# STM32WBA25 register map
File version: 1.0
CPU: CM33 r0p1, little endian, MPU, FPU, 4 interrupt priority bits
Registers are 32-bit, read-write, reset 0x0 unless marked. A register's access mark holds for its fields unless they carry their own. Offsets are from the block's base; [hi:lo] are bit positions; {n}, {i} and the like mark numbered series.

## SYSCFG — SYSCFG address block description
Base 0x46000400
Same registers: SEC_SYSCFG 0x56000400
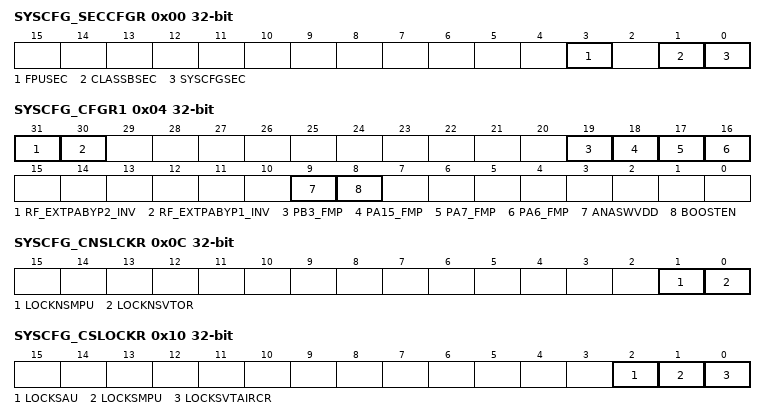
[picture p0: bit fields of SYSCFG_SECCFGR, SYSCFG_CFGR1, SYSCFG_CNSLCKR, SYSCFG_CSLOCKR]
0x00 SYSCFG_SECCFGR — SYSCFG secure configuration register
  [3] FPUSEC — FPU security
    0=SYSCFG_FPUIMR register can be read and written by secure and nonsecure access; 1=SYSCFG_FPUIMR register can be read and written by secure access only
  [1] CLASSBSEC — Class B security
    0=SYSCFG_CFGR2 register can be read and written by secure and nonsecure access; 1=SYSCFG_CFGR2 register can be read and written by secure access only
  [0] SYSCFGSEC — SYSCFG clock control, memory erase status and compensation cell registers security
    0=SYSCFG configuration clock in RCC registers, SYSCFG_MESR and SYSCFG_CCCSR, SYSCFG_CCVR and SYSCFG_CCCR can be read and written by secure and nonsecure access; 1=SYSCFG configuration clock in RCC registers, SYSCFG_MESR and SYSCFG_CCCSR, SYSCFG_CCVR and SYSCFG_CCCR can be read and written by secure access only
0x04 SYSCFG_CFGR1 — SYSCFG configuration register 1
  [31] RF_EXTPABYP2_INV — signal RF_EXTPABYP2 inversion selection.
    0=RF_EXTPABYP2 not inverted; 1=RF_EXTPABYP2 inverted
  [30] RF_EXTPABYP1_INV — signal RF_EXTPABYP1 inversion selection.
    0=RF_EXTPABYP1 not inverted; 1=RF_EXTPABYP1 inverted
  [19] PB3_FMP — Fast-mode Plus drive capability activation on PB3
    0=PB3 pin operates in standard mode when not used by I2C peripheral; 1=Fast-mode Plus mode is enabled on PAB3 pin and the GPIO speed control is bypassed
  [18] PA15_FMP — Fast-mode Plus drive capability activation on PA15
    0=PA15 pin operates in standard mode when not used by I2C peripheral; 1=Fast-mode Plus mode is enabled on PA15 pin and the GPIO speed control is bypassed
  [17] PA7_FMP — Fast-mode Plus drive capability activation on PA7
    0=PA7 pin operates in standard mode when not used by I2C peripheral; 1=Fast-mode Plus mode is enabled on PA7 pin and the GPIO speed control is bypassed
  [16] PA6_FMP — Fast-mode Plus drive capability activation on PA6
    0=PA6 pin operates in standard mode when not used by I2C peripheral; 1=Fast-mode Plus mode is enabled on PA6 pin and the GPIO speed control is bypassed
  [9] ANASWVDD — GPIO analog switch control voltage selection
    0=I/O analog switches are supplied by V<sub>DDA</sub> or booster when booster is ON; 1=I/O analog switches are supplied by V<sub>DD</sub>
  [8] BOOSTEN — I/O analog switch voltage booster enable
    0=I/O analog switches are supplied by V<sub>DDA</sub> voltage; 1=I/O analog switches are supplied by a dedicated voltage booster (supplied by V<sub>DD</sub>)
0x08 SYSCFG_FPUIMR reset 0x1F — SYSCFG FPU interrupt mask register
  [5:0] FPU_IE — Floating point unit interrupts enable bits
0x0C SYSCFG_CNSLCKR — SYSCFG CPU nonsecure lock register
  [1] LOCKNSMPU — MPU registers lock
    0=Nonsecure MPU registers write enabled; 1=Nonsecure MPU registers write disabled
  [0] LOCKNSVTOR — VTOR register lock
    0=VTOR register write enabled; 1=VTOR register write disabled
0x10 SYSCFG_CSLOCKR — SYSCFG CPU secure lock register
  [2] LOCKSAU — SAU registers lock
    0=SAU registers write enabled; 1=SAU registers write disabled
  [1] LOCKSMPU — Secure MPU registers lock
    0=Secure MPU registers writes enabled; 1=Secure MPU registers writes disabled
  [0] LOCKSVTAIRCR — VTOR_S register and AIRCR register bits lock
    0=VTOR_S register PRIS and BFHFNMINS bits in the AIRCR register write enabled; 1=VTOR_S register PRIS and BFHFNMINS bits in the AIRCR register write disabled
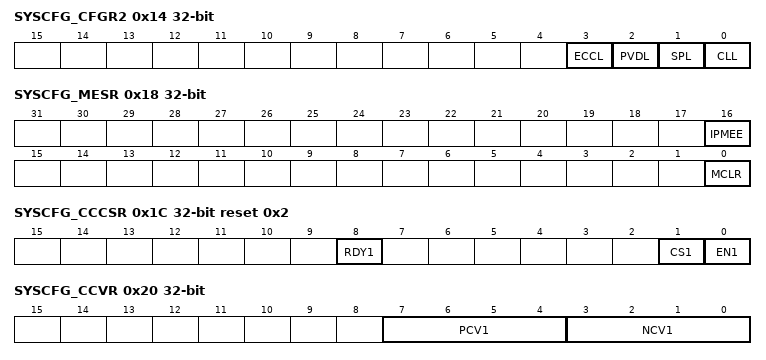
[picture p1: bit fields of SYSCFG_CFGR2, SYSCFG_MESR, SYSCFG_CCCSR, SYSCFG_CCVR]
0x14 SYSCFG_CFGR2 — SYSCFG configuration register 2
  [3] ECCL — ECC lock
    0=ECC double error disconnected from TIM16 and TIM17 break input; 1=ECC double error connected to TIM16 and TIM17 break input
  [2] PVDL — PVD lock enable bit
    0=PVD interrupt disconnected from TIM16 and TIM17 break input; 1=PVD interrupt connected to TIM16 and TIM17 break input
  [1] SPL — SRAM2 parity lock bit
    0=SRAM2 parity error disconnected from TIM16 and TIM17 break inputs; 1=SRAM2 parity error connected to TIM16 and TIM17 break inputs
  [0] CLL — Cortex-M33 LOCKUP (hardfault) output enable
    0=Cortex-M33 LOCKUP output disconnected from TIM16 to TIM17 break inputs; 1=Cortex-M33 LOCKUP output connected to TIM16 and TIM17 break inputs
0x18 SYSCFG_MESR — SYSCFG memory erase status register
  [16] IPMEE — ICACHE and PKA SRAM erase status
    0=ICACHE and PKA SRAM erase on going if not yet cleared by software; 1=ICACHE and PKA SRAM erase done
  [0] MCLR — Device memories erase status
    0=Memory erase ongoing if not yet cleared by software; 1=Memory erase done
0x1C SYSCFG_CCCSR reset 0x2 — SYSCFG compensation cell control/status register
  [8] RDY1 ro — VDD I/Os compensation cell ready flag
    0=VDD I/Os compensation cell not ready; 1=VDD I/Os compensation cell ready
  [1] CS1 — VDD I/Os code selection
    0=VDD I/Os code from the cell (available in the SYSCFG_CCVR); 1=VDD I/Os code from the SYSCFG compensation cell code register (SYSCFG_CCCR)
  [0] EN1 — VDD I/Os compensation cell enable
    0=VDD I/Os compensation cell disabled; 1=VDD I/Os compensation cell enabled
0x20 SYSCFG_CCVR ro — SYSCFG compensation cell value register
  [7:4] PCV1 — PMOS compensation value of the I/Os supplied by V<sub>DD</sub>
  [3:0] NCV1 — NMOS compensation value of the I/Os supplied by V<sub>DD</sub>
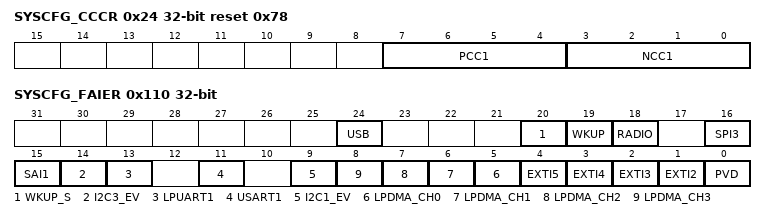
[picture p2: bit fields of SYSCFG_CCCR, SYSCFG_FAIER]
0x24 SYSCFG_CCCR reset 0x78 — SYSCFG compensation cell code register
  [7:4] PCC1 — PMOS compensation code of the I/Os supplied by V<sub>DD</sub>
  [3:0] NCC1 — NMOS compensation code of the I/Os supplied by V<sub>DD</sub>
0x2C SYSCFG_RSSCMDR — SYSCFG RSS command register
  [15:0] RSSCMD — RSS commands
0x110 SYSCFG_FAIER — SYSCFG flash abort interrupt enable register
  [24] USB — enable USB interrupt to abort Flash operation.
    0=USB interrupt abort Flash operation disabled; 1=USB interrupt abort Flash operation enabled
  [20] WKUP_S — enable PWR WKUP secure interrupt to abort Flash operation.
    0=PWR WKUP secure interrupt abort Flash operation disabled; 1=PWR WKUP secure interrupt abort Flash operation enabled
  [19] WKUP — enable PWR WKUP interrupt to abort Flash operation.
    0=PWR WKUP interrupt abort Flash operation disabled; 1=PWR WKUP interrupt abort Flash operation enabled
  [18] RADIO — enable RADIO interrupt to abort Flash operation.
    0=RADIO interrupt abort Flash operation disabled; 1=RADIO interrupt abort Flash operation enabled
  [16] SPI3 — enable SPI3 interrupt to abort Flash operation.
    0=SPI3 interrupt abort Flash operation disabled; 1=SPI3 interrupt abort Flash operation enabled
  [15] SAI1 — enable SAI1 interrupt to abort Flash operation.
    0=SAI1 interrupt abort Flash operation disabled; 1=SAI1 interrupt abort Flash operation enabled
  [14] I2C3_EV — enable I2C3_EV interrupt to abort Flash operation.
    0=I2C3_EV interrupt abort Flash operation disabled; 1=I2C3_EV interrupt abort Flash operation enabled
  [13] LPUART1 — enable LPUART1 interrupt to abort Flash operation.
    0=LPUART1 interrupt abort Flash operation disabled; 1=LPUART1 interrupt abort Flash operation enabled
  [11] USART1 — enable USART1 interrupt to abort Flash operation.
    0=USART1 interrupt abort Flash operation disabled; 1=USART1 interrupt abort Flash operation enabled
  [9] I2C1_EV — enable I2C1_EV interrupt to abort Flash operation.
    0=I2C1_EV interrupt abort Flash operation disabled; 1=I2C1_EV interrupt abort Flash operation enabled
  [n+5] LPDMA_CH{n} (n=0..3) — enable LPDMA_CH{n} interrupt to abort Flash operation.
    0=LPDMA_CH{n} interrupt abort Flash operation disabled; 1=LPDMA_CH{n} interrupt abort Flash operation enabled
  [n-1] EXTI{n} (n=2..5) — enable EXTI{n} interrupt to abort Flash operation.
    0=EXTI{n} interrupt abort Flash operation disabled; 1=EXTI{n} interrupt abort Flash operation enabled
  [0] PVD — enable EXTI16 PVD interrupt to abort Flash operation.
    0=PVD EXTI16 interrupt abort Flash operation disabled; 1=PVD EXTI16 interrupt abort Flash operation enabled
